# GD32F50x register map
File version: 1.0
CPU: CM33 r2p1, little endian, MPU, FPU, 4 interrupt priority bits
Registers are 32-bit, read-write, reset 0x0 unless marked. A register's access mark holds for its fields unless they carry their own. Offsets are from the block's base; [hi:lo] are bit positions; {n}, {i} and the like mark numbered series; 'fields as' and 'values as' point back to an identical list.

## SYSCFG — System and memory architecture
Base 0x40014000
0x00 CFG0 ro — Configuration register 0
  [2:0] BOOT_MODE
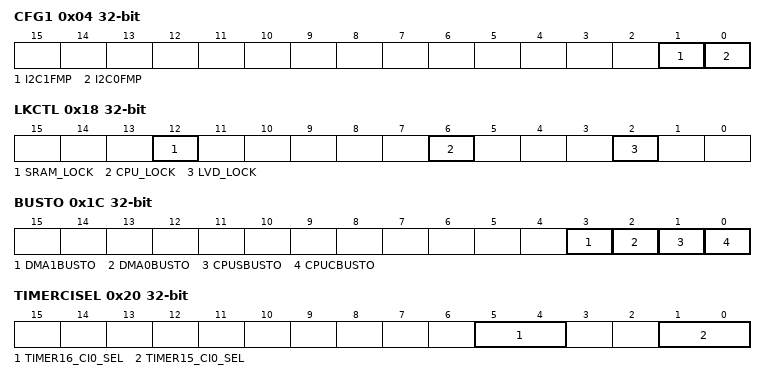
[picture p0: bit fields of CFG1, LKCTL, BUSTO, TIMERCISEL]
0x04 CFG1 — Configuration register 1
  [1] I2C1FMP — I2C1 Fm+
  [0] I2C0FMP — I2C0 Fm+
0x18 LKCTL — Lockup control register
  [12] SRAM_LOCK — SRAM ECC double error lockup bit
  [6] CPU_LOCK — CPU lockup bit
  [2] LVD_LOCK — Low voltage detector lockup bit
0x1C BUSTO — Bus timeout register
  [3] DMA1BUSTO — DMA1 bus timeout enable bit.
  [2] DMA0BUSTO — DMA0 bus timeout enable bit.
  [1] CPUSBUSTO — CPU Sbus timeout enable bit.
  [0] CPUCBUSTO — CPU Cbus timeout enable bit.
0x20 TIMERCISEL — Timer input selection register
  [5:4] TIMER16_CI0_SEL — Selects TIMER16_CI0 input selection
  [1:0] TIMER15_CI0_SEL — Selects TIMER15_CI0 input selection
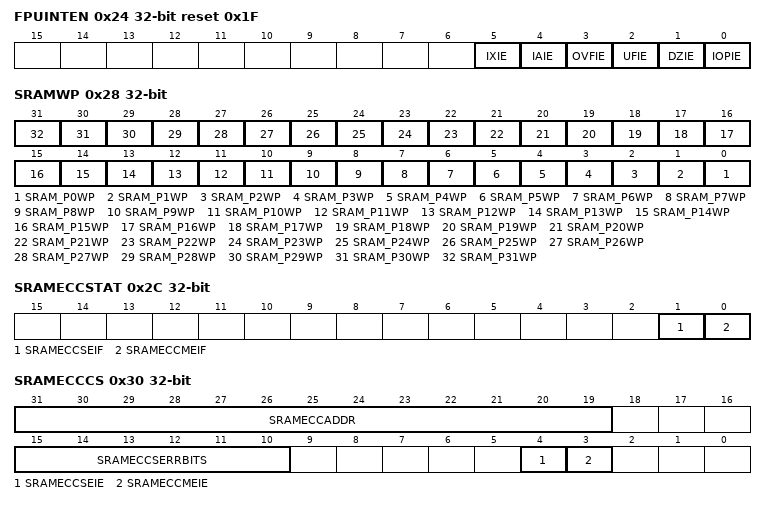
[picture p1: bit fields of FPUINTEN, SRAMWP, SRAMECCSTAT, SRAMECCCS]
0x24 FPUINTEN reset 0x1F — FPU interrupt enable register
  [5] IXIE — Inexact interrupt enable bit
  [4] IAIE — Input abnormal interrupt enable bit
  [3] OVFIE — Overflow interrupt enable bit
  [2] UFIE — Underflow interrupt enable bit
  [1] DZIE — Divide by 0 interrupt enable bit
  [0] IOPIE — Invalid operation interrupt enable bit
0x28 SRAMWP — SRAM write protection register
  [n] SRAM_P{n}WP (n=0..31) — SRAM page {n} write protection
0x2C SRAMECCSTAT — SRAM ECC status register
  [1] SRAMECCSEIF — Indicates the single-bit error
  [0] SRAMECCMEIF — Indicates the multi-bit error
0x30 SRAMECCCS access per field — SRAM ECC control and status register
  [31:19] SRAMECCADDR ro — Record the faulting system address where the last ECC event on SRAM occurred.
  [15:10] SRAMECCSERRBITS ro — Indicates the error bit
  [4] SRAMECCSEIE rw — SRAM single bit correction interrupt enable
  [3] SRAMECCMEIE rw — SRAM multi-bit non-correction interrupt enable
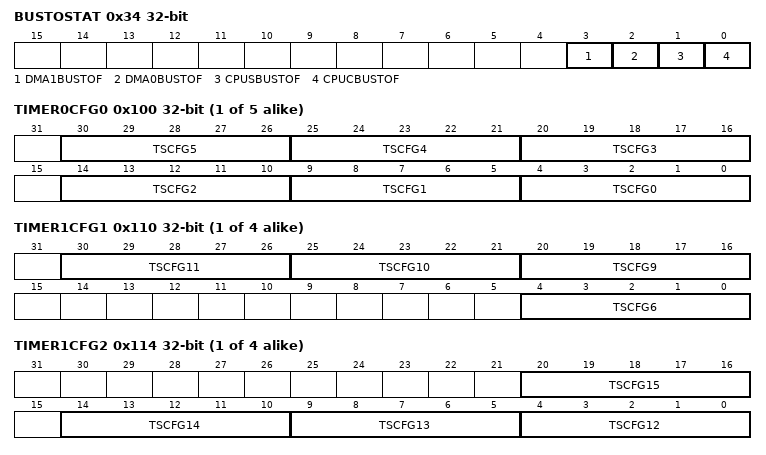
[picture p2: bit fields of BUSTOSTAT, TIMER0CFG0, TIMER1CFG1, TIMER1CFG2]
0x34 BUSTOSTAT — Bus timeout status register
  [3] DMA1BUSTOF — DMA1 bus timeout flag.
  [2] DMA0BUSTOF — DMA0 bus timeout flag.
  [1] CPUSBUSTOF — CPU Sbus timeout flag.
  [0] CPUCBUSTOF — CPU Cbus timeout flag.
{0x100+0xC*i} TIMER{i}CFG0 (i=0..4) — TIMERx configuration register 0
  [30:26] TSCFG5 — Event mode configuration
  [25:21] TSCFG4 — Pause mode configuration
  [20:16] TSCFG3 — Restart mode configuration
  [14:10] TSCFG2 — Quadrature decoder mode 2 configuration
  [9:5] TSCFG1 — Quadrature decoder mode 1 configuration
  [4:0] TSCFG0 — Quadrature decoder mode 0 configuration
0x104 TIMER0CFG1 — TIMERx configuration register 1
  [4:0] TSCFG6 — External clock mode 0 configuration
0x108 TIMER0CFG2 — TIMERx configuration register 2
  [20:16] TSCFG15 — Internal trigger input source configuration
{0x104+0xC*i} TIMER{i}CFG1 (i=1..4) — TIMERx configuration register 1
  [30:26] TSCFG11 — Decoder mode 2 configuration
  [25:21] TSCFG10 — Decoder mode 1 configuration
  [20:16] TSCFG9 — Decoder mode 0 configuration
  [4:0] TSCFG6 — External clock mode 0 configuration
{0x108+0xC*i} TIMER{i}CFG2 (i=1..4) — TIMERx configuration register 2
  [20:16] TSCFG15 — Internal trigger input source configuration
  [14:10] TSCFG14 — Quadrature decoder mode 4 configuration
  [9:5] TSCFG13 — Quadrature decoder mode 3 configuration
  [4:0] TSCFG12 — Decoder mode 3 configuration
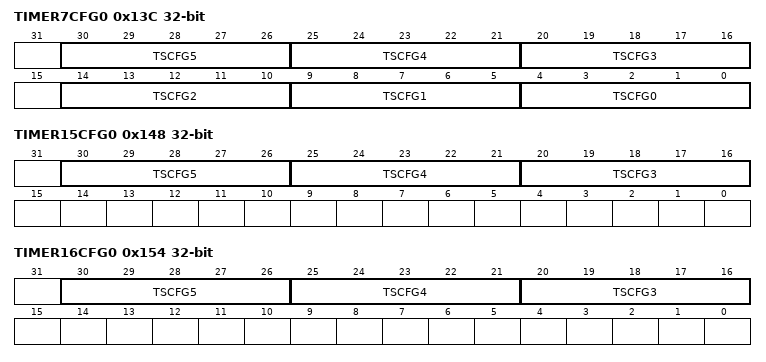
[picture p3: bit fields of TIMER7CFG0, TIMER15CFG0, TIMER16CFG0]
0x13C TIMER7CFG0 — TIMERx configuration register 0
  fields as TIMER0CFG0
0x140 TIMER7CFG1 — TIMERx configuration register 1
  [4:0] TSCFG6 — External clock mode 0 configuration
0x144 TIMER7CFG2 — TIMERx configuration register 2
  [20:16] TSCFG15 — Internal trigger input source configuration
0x148 TIMER15CFG0 — TIMERx configuration register 0
  [30:26] TSCFG5 — Event mode configuration
  [25:21] TSCFG4 — Pause mode configuration
  [20:16] TSCFG3 — Restart mode configuration
0x14C TIMER15CFG1 — TIMERx configuration register 1
  [4:0] TSCFG6 — External clock mode 0 configuration
0x150 TIMER15CFG2 — TIMERx configuration register 2
  [20:16] TSCFG15 — Internal trigger input source configuration
0x154 TIMER16CFG0 — TIMERx configuration register 0
  fields as TIMER15CFG0
0x158 TIMER16CFG1 — TIMERx configuration register 1
  [4:0] TSCFG6 — External clock mode 0 configuration
0x15C TIMER16CFG2 — TIMERx configuration register 2
  [20:16] TSCFG15 — Internal trigger input source configuration
